# ATSAMA5D31 register map
Vendor: Atmel; Series: SAMA5D3; File version: 20130221
Registers are 32-bit, read-write, reset 0x0 unless marked. A register's access mark holds for its fields unless they carry their own. Offsets are from the block's base; [hi:lo] are bit positions; {n}, {i} and the like mark numbered series; 'fields as' and 'values as' point back to an identical list.

## EMAC — Ethernet MAC 10/100
Base 0xF802C000; register names take the prefix EMAC_
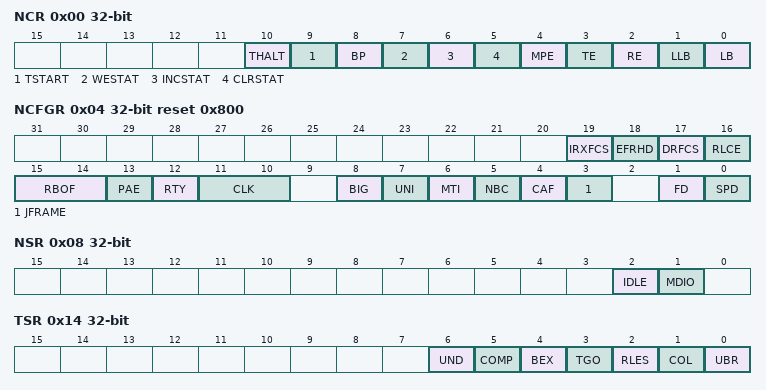
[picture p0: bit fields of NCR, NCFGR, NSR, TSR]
0x00 NCR — Network Control Register
  [10] THALT — Transmit halt
  [9] TSTART — Start transmission
  [8] BP — Back pressure
  [7] WESTAT — Write enable for statistics registers
  [6] INCSTAT — Increment statistics registers
  [5] CLRSTAT — Clear statistics registers
  [4] MPE — Management port enable
  [3] TE — Transmit enable
  [2] RE — Receive enable
  [1] LLB — Loopback local
  [0] LB — LoopBack
0x04 NCFGR reset 0x800 — Network Configuration Register
  [19] IRXFCS — Ignore RX FCS
  [18] EFRHD
  [17] DRFCS — Discard Receive FCS
  [16] RLCE — Receive Length field Checking Enable
  [15:14] RBOF — Receive Buffer Offset
    0=OFFSET_0 (No offset from start of receive buffer.); 1=OFFSET_1 (One-byte offset from start of receive buffer.); 2=OFFSET_2 (Two-byte offset from start of receive buffer.); 3=OFFSET_3 (Three-byte offset from start of receive buffer.)
  [13] PAE — Pause Enable
  [12] RTY — Retry test
  [11:10] CLK — MDC clock divider
    0=MCK_8 (MCK divided by 8 (MCK up to 20 MHz).); 1=MCK_16 (MCK divided by 16 (MCK up to 40 MHz).); 2=MCK_32 (MCK divided by 32 (MCK up to 80 MHz).); 3=MCK_64 (MCK divided by 64 (MCK up to 160 MHz).)
  [8] BIG — Receive 1536 bytes frames
  [7] UNI — Unicast Hash Enable
  [6] MTI — Multicast Hash Enable
  [5] NBC — No Broadcast
  [4] CAF — Copy All Frames
  [3] JFRAME — Jumbo Frames
  [1] FD — Full Duplex
  [0] SPD — Speed
0x08 NSR ro reset not defined — Network Status Register
  [2] IDLE, [1] MDIO
0x14 TSR — Transmit Status Register
  [6] UND — Transmit Underrun
  [5] COMP — Transmit Complete
  [4] BEX — Buffers exhausted mid frame
  [3] TGO — Transmit Go
  [2] RLES — Retry Limit exceeded
  [1] COL — Collision Occurred
  [0] UBR — Used Bit Read
0x18 RBQP — Receive Buffer Queue Pointer Register
  [31:2] ADDR — Receive buffer queue pointer address
0x1C TBQP — Transmit Buffer Queue Pointer Register
  [31:2] ADDR — Transmit buffer queue pointer address
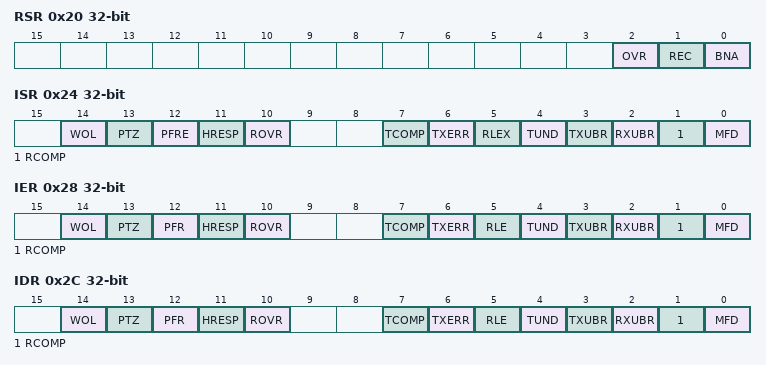
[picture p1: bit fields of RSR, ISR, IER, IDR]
0x20 RSR — Receive Status Register
  [2] OVR — Receive Overrun
  [1] REC — Frame Received
  [0] BNA — Buffer Not Available
0x24 ISR — Interrupt Status Register
  [14] WOL — Wake On LAN
  [13] PTZ — Pause Time Zero
  [12] PFRE — Pause Frame Received
  [11] HRESP — Hresp not OK
  [10] ROVR — Receive Overrun
  [7] TCOMP — Transmit Complete
  [6] TXERR — Transmit Error
  [5] RLEX — Retry Limit Exceeded
  [4] TUND — Ethernet Transmit Buffer Underrun
  [3] TXUBR — Transmit Used Bit Read
  [2] RXUBR — Receive Used Bit Read
  [1] RCOMP — Receive Complete
  [0] MFD — Management Frame Done
0x28 IER wo reset not defined — Interrupt Enable Register
  [14] WOL — Wake On LAN
  [13] PTZ — Pause Time Zero
  [12] PFR — Pause Frame Received
  [11] HRESP — Hresp not OK
  [10] ROVR — Receive Overrun
  [7] TCOMP — Transmit Complete
  [6] TXERR
  [5] RLE — Retry Limit Exceeded
  [4] TUND — Ethernet Transmit Buffer Underrun
  [3] TXUBR — Transmit Used Bit Read
  [2] RXUBR — Receive Used Bit Read
  [1] RCOMP — Receive Complete
  [0] MFD — Management Frame sent
0x2C IDR wo reset not defined — Interrupt Disable Register
  fields as IER
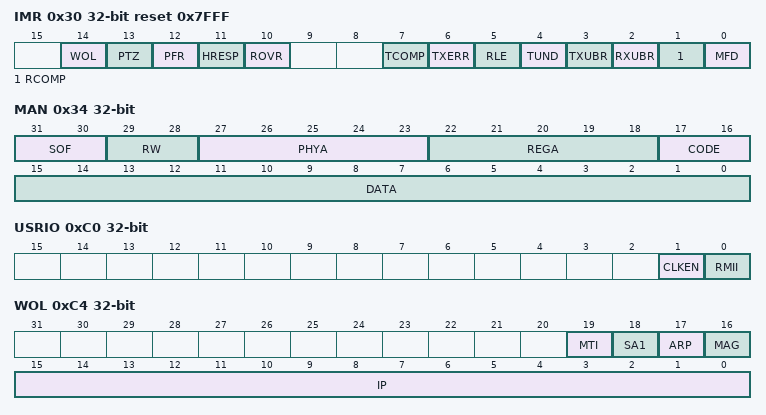
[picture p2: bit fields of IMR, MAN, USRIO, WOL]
0x30 IMR ro reset 0x7FFF — Interrupt Mask Register
  fields as IER
0x34 MAN — Phy Maintenance Register
  [31:30] SOF — Start of frame
  [29:28] RW — Read-write
  [27:23] PHYA — PHY Address
  [22:18] REGA — Register Address
  [17:16] CODE
  [15:0] DATA
0x38 PTR — Pause Time Register
  [15:0] PTIME — Pause Time
0x3C PFR — Pause Frames Received Register
  [15:0] FROK — Pause Frames received OK
0x40 FTO — Frames Transmitted Ok Register
  [23:0] FTOK — Frames Transmitted OK
0x44 SCF — Single Collision Frames Register
  [15:0] SCF — Single Collision Frames
0x48 MCF — Multiple Collision Frames Register
  [15:0] MCF — Multicollision Frames
0x4C FRO — Frames Received Ok Register
  [23:0] FROK — Frames Received OK
0x50 FCSE — Frame Check Sequence Errors Register
  [7:0] FCSE — Frame Check Sequence Errors
0x54 ALE — Alignment Errors Register
  [7:0] ALE — Alignment Errors
0x58 DTF — Deferred Transmission Frames Register
  [15:0] DTF — Deferred Transmission Frames
0x5C LCOL — Late Collisions Register
  [7:0] LCOL — Late Collisions
0x60 ECOL — Excessive Collisions Register
  [7:0] EXCOL — Excessive Collisions
0x64 TUND — Transmit Underrun Errors Register
  [7:0] TUND — Transmit Underruns
0x68 CSE — Carrier Sense Errors Register
  [7:0] CSE — Carrier Sense Errors
0x6C RRE — Receive Resource Errors Register
  [15:0] RRE — Receive Resource Errors
0x70 ROV — Receive Overrun Errors Register
  [7:0] ROVR — Receive Overrun
0x74 RSE — Receive Symbol Errors Register
  [7:0] RSE — Receive Symbol Errors
0x78 ELE — Excessive Length Errors Register
  [7:0] EXL — Excessive Length Errors
0x7C RJA — Receive Jabbers Register
  [7:0] RJB — Receive Jabbers
0x80 USF — Undersize Frames Register
  [7:0] USF — Undersize frames
0x84 STE — SQE Test Errors Register
  [7:0] SQER — SQE test errors
0x88 RLE — Received Length Field Mismatch Register
  [7:0] RLFM — Receive Length Field Mismatch
0x90 HRB — Hash Register Bottom [31:0] Register
  [31:0] ADDR
0x94 HRT — Hash Register Top [63:32] Register
  [31:0] ADDR
{0x90+8i} SA{i}B (i=1..4) — Specific Address {i} Bottom Register
  [31:0] ADDR
{0x94+8i} SA{i}T (i=1..4) — Specific Address {i} Top Register
  [15:0] ADDR
0xB8 TID — Type ID Checking Register
  [15:0] TID — Type ID checking
0xC0 USRIO — User Input/Output Register
  [1] CLKEN — Clock Enable
  [0] RMII — Reduce MII
0xC4 WOL — Wake on LAN Register
  [19] MTI — Multicast hash event enable
  [18] SA1 — Specific address register 1 event enable
  [17] ARP — ARP request IP address
  [16] MAG — Magic packet event enable
  [15:0] IP — ARP request IP address
